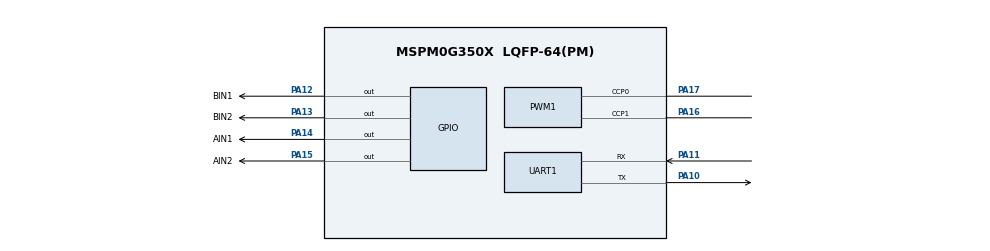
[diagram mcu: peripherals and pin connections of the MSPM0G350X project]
/**
 * @cliArgs --device "MSPM0G350X" --part "Default" --package "LQFP-64(PM)" --product "mspm0_sdk@2.05.01.01"
 * @versions {"tool":"1.24.0+4110"}
 */

/**
 * Import the modules used in this configuration.
 */
const GPIO   = scripting.addModule("/ti/driverlib/GPIO", {}, false);
const GPIO1  = GPIO.addInstance();
const GPIO2  = GPIO.addInstance();
const GPIO3  = GPIO.addInstance();
const GPIO4  = GPIO.addInstance();
const GPIO5  = GPIO.addInstance();
const GPIO6  = GPIO.addInstance();
const GPIO7  = GPIO.addInstance();
const GPIO8  = GPIO.addInstance();
const GPIO9  = GPIO.addInstance();
const PWM    = scripting.addModule("/ti/driverlib/PWM", {}, false);
const PWM1   = PWM.addInstance();
const SYSCTL = scripting.addModule("/ti/driverlib/SYSCTL");
const TIMER  = scripting.addModule("/ti/driverlib/TIMER", {}, false);
const TIMER1 = TIMER.addInstance();
const UART   = scripting.addModule("/ti/driverlib/UART", {}, false);
const UART1  = UART.addInstance();

/**
 * Write custom configuration values to the imported modules.
 */
const divider9       = system.clockTree["UDIV"];
divider9.divideValue = 2;

const mux4       = system.clockTree["EXHFMUX"];
mux4.inputSelect = "EXHFMUX_XTAL";

const mux8       = system.clockTree["HSCLKMUX"];
mux8.inputSelect = "HSCLKMUX_SYSPLL2X";

const mux12       = system.clockTree["SYSPLLMUX"];
mux12.inputSelect = "zSYSPLLMUX_HFCLK";

const pinFunction4        = system.clockTree["HFXT"];
pinFunction4.inputFreq    = 40;
pinFunction4.enable       = true;
pinFunction4.HFCLKMonitor = true;
pinFunction4.HFXTStartup  = 20;

GPIO1.$name                          = "LED1";
GPIO1.associatedPins[0].ioStructure  = "SD";
GPIO1.associatedPins[0].assignedPort = "PORTB";
GPIO1.associatedPins[0].assignedPin  = "22";
GPIO1.associatedPins[0].$name        = "PIN_22";

const Board = scripting.addModule("/ti/driverlib/Board", {}, false);

GPIO2.$name                          = "TB6612";
GPIO2.port                           = "PORTA";
GPIO2.associatedPins.create(4);
GPIO2.associatedPins[0].$name        = "AIN1";
GPIO2.associatedPins[0].initialValue = "SET";
GPIO2.associatedPins[0].assignedPin  = "14";
GPIO2.associatedPins[0].pin.$assign  = "PA14";
GPIO2.associatedPins[1].$name        = "AIN2";
GPIO2.associatedPins[1].initialValue = "SET";
GPIO2.associatedPins[1].assignedPin  = "15";
GPIO2.associatedPins[1].pin.$assign  = "PA15";
GPIO2.associatedPins[2].$name        = "BIN1";
GPIO2.associatedPins[2].initialValue = "SET";
GPIO2.associatedPins[2].assignedPin  = "12";
GPIO2.associatedPins[2].pin.$assign  = "PA12";
GPIO2.associatedPins[3].$name        = "BIN2";
GPIO2.associatedPins[3].initialValue = "SET";
GPIO2.associatedPins[3].assignedPin  = "13";
GPIO2.associatedPins[3].pin.$assign  = "PA13";

GPIO3.$name                          = "ENCODER1A";
GPIO3.associatedPins[0].direction    = "INPUT";
GPIO3.associatedPins[0].assignedPort = "PORTA";
GPIO3.associatedPins[0].assignedPin  = "21";
GPIO3.associatedPins[0].interruptEn  = true;
GPIO3.associatedPins[0].polarity     = "FALL";
GPIO3.associatedPins[0].$name        = "A1";

GPIO4.$name                          = "ENCODER1B";
GPIO4.associatedPins[0].direction    = "INPUT";
GPIO4.associatedPins[0].assignedPort = "PORTB";
GPIO4.associatedPins[0].polarity     = "FALL";
GPIO4.associatedPins[0].assignedPin  = "18";
GPIO4.associatedPins[0].$name        = "B1";

GPIO5.$name                          = "ENCODER2A";
GPIO5.associatedPins[0].direction    = "INPUT";
GPIO5.associatedPins[0].$name        = "A2";
GPIO5.associatedPins[0].assignedPort = "PORTB";
GPIO5.associatedPins[0].assignedPin  = "23";
GPIO5.associatedPins[0].interruptEn  = true;
GPIO5.associatedPins[0].polarity     = "FALL";

GPIO6.$name                          = "ENCODER2B";
GPIO6.associatedPins[0].$name        = "B2";
GPIO6.associatedPins[0].direction    = "INPUT";
GPIO6.associatedPins[0].assignedPort = "PORTB";
GPIO6.associatedPins[0].assignedPin  = "26";

GPIO7.port                          = "PORTA";
GPIO7.$name                         = "SENSOR";
GPIO7.associatedPins.create(5);
GPIO7.associatedPins[0].direction   = "INPUT";
GPIO7.associatedPins[0].assignedPin = "24";
GPIO7.associatedPins[0].$name       = "A";
GPIO7.associatedPins[1].direction   = "INPUT";
GPIO7.associatedPins[1].assignedPin = "25";
GPIO7.associatedPins[1].$name       = "B";
GPIO7.associatedPins[2].direction   = "INPUT";
GPIO7.associatedPins[2].assignedPin = "26";
GPIO7.associatedPins[2].$name       = "C";
GPIO7.associatedPins[3].direction   = "INPUT";
GPIO7.associatedPins[3].assignedPin = "27";
GPIO7.associatedPins[3].$name       = "D";
GPIO7.associatedPins[4].$name       = "E";
GPIO7.associatedPins[4].direction   = "INPUT";
GPIO7.associatedPins[4].assignedPin = "22";

GPIO8.$name                         = "SENSOR2";
GPIO8.port                          = "PORTB";
GPIO8.associatedPins.create(2);
GPIO8.associatedPins[0].$name       = "L";
GPIO8.associatedPins[0].direction   = "INPUT";
GPIO8.associatedPins[0].assignedPin = "24";
GPIO8.associatedPins[1].$name       = "R";
GPIO8.associatedPins[1].direction   = "INPUT";
GPIO8.associatedPins[1].assignedPin = "25";

GPIO9.$name                              = "KEY";
GPIO9.associatedPins.create(6);
GPIO9.associatedPins[0].$name            = "KEY1";
GPIO9.associatedPins[0].direction        = "INPUT";
GPIO9.associatedPins[0].internalResistor = "PULL_UP";
GPIO9.associatedPins[0].assignedPort     = "PORTA";
GPIO9.associatedPins[0].interruptEn      = true;
GPIO9.associatedPins[0].assignedPin      = "28";
GPIO9.associatedPins[0].polarity         = "RISE";
GPIO9.associatedPins[1].$name            = "KEY2";
GPIO9.associatedPins[1].direction        = "INPUT";
GPIO9.associatedPins[1].internalResistor = "PULL_UP";
GPIO9.associatedPins[1].assignedPort     = "PORTA";
GPIO9.associatedPins[1].interruptEn      = true;
GPIO9.associatedPins[1].polarity         = "RISE";
GPIO9.associatedPins[1].assignedPin      = "31";
GPIO9.associatedPins[2].$name            = "KEY3";
GPIO9.associatedPins[2].direction        = "INPUT";
GPIO9.associatedPins[2].internalResistor = "PULL_UP";
GPIO9.associatedPins[2].interruptEn      = true;
GPIO9.associatedPins[2].polarity         = "RISE";
GPIO9.associatedPins[2].assignedPort     = "PORTA";
GPIO9.associatedPins[2].assignedPin      = "8";
GPIO9.associatedPins[3].internalResistor = "PULL_UP";
GPIO9.associatedPins[3].direction        = "INPUT";
GPIO9.associatedPins[3].interruptEn      = true;
GPIO9.associatedPins[3].polarity         = "RISE";
GPIO9.associatedPins[3].assignedPort     = "PORTA";
GPIO9.associatedPins[3].assignedPin      = "9";
GPIO9.associatedPins[3].$name            = "KEY4";
GPIO9.associatedPins[4].$name            = "KEY5";
GPIO9.associatedPins[4].direction        = "INPUT";
GPIO9.associatedPins[4].interruptEn      = true;
GPIO9.associatedPins[4].polarity         = "RISE";
GPIO9.associatedPins[4].internalResistor = "PULL_UP";
GPIO9.associatedPins[4].assignedPort     = "PORTB";
GPIO9.associatedPins[4].assignedPin      = "6";
GPIO9.associatedPins[5].$name            = "KEY6";
GPIO9.associatedPins[5].direction        = "INPUT";
GPIO9.associatedPins[5].assignedPort     = "PORTB";
GPIO9.associatedPins[5].assignedPin      = "7";
GPIO9.associatedPins[5].interruptEn      = true;
GPIO9.associatedPins[5].polarity         = "RISE";
GPIO9.associatedPins[5].internalResistor = "PULL_UP";

PWM1.$name                      = "PWM_0";
PWM1.timerStartTimer            = true;
PWM1.clockDivider               = 8;
PWM1.peripheral.$assign         = "TIMA1";
PWM1.peripheral.ccp0Pin.$assign = "PA17";
PWM1.peripheral.ccp1Pin.$assign = "PA16";
PWM1.PWM_CHANNEL_0.$name        = "ti_driverlib_pwm_PWMTimerCC0";
PWM1.PWM_CHANNEL_0.invert       = true;
PWM1.PWM_CHANNEL_1.$name        = "ti_driverlib_pwm_PWMTimerCC1";
PWM1.PWM_CHANNEL_1.invert       = true;
PWM1.ccp0PinConfig.$name        = "ti_driverlib_gpio_GPIOPinGeneric2";
PWM1.ccp1PinConfig.$name        = "ti_driverlib_gpio_GPIOPinGeneric3";

SYSCTL.forceDefaultClkConfig = true;
SYSCTL.clockTreeEn           = true;
SYSCTL.validateClkStatus     = true;
scripting.suppress("For best practices when the CPUCLK is running at 32MHz and above, clear the flash status bit using DL_FlashCTL_executeClearStatus\\(\\) before executing any flash operation\\. Otherwise there may be false positives\\.", SYSCTL);

TIMER1.$name              = "TIMER_0";
TIMER1.timerClkPrescale   = 250;
TIMER1.timerStartTimer    = true;
TIMER1.interrupts         = ["ZERO"];
TIMER1.timerClkDiv        = 4;
TIMER1.timerMode          = "PERIODIC";
TIMER1.timerPeriod        = "500 ms";
TIMER1.peripheral.$assign = "TIMG0";

UART1.$name                        = "UART_0";
UART1.targetBaudRate               = 115200;
UART1.peripheral.$assign           = "UART0";
UART1.peripheral.rxPin.$assign     = "PA11";
UART1.peripheral.txPin.$assign     = "PA10";
UART1.txPinConfig.$name            = "ti_driverlib_gpio_GPIOPinGeneric0";
UART1.txPinConfig.enableConfig     = true;
UART1.txPinConfig.internalResistor = "PULL_UP";
UART1.rxPinConfig.$name            = "ti_driverlib_gpio_GPIOPinGeneric1";
UART1.rxPinConfig.enableConfig     = true;
UART1.rxPinConfig.internalResistor = "PULL_UP";

/**
 * Pinmux solution for unlocked pins/peripherals. This ensures that minor changes to the automatic solver in a future
 * version of the tool will not impact the pinmux you originally saw.  These lines can be completely deleted in order to
 * re-solve from scratch.
 */
pinFunction4.peripheral.$suggestSolution           = "SYSCTL";
pinFunction4.peripheral.hfxInPin.$suggestSolution  = "PA5";
pinFunction4.peripheral.hfxOutPin.$suggestSolution = "PA6";
GPIO1.associatedPins[0].pin.$suggestSolution       = "PB22";
Board.peripheral.$suggestSolution                  = "DEBUGSS";
Board.peripheral.swclkPin.$suggestSolution         = "PA20";
Board.peripheral.swdioPin.$suggestSolution         = "PA19";
GPIO3.associatedPins[0].pin.$suggestSolution       = "PA21";
GPIO4.associatedPins[0].pin.$suggestSolution       = "PB18";
GPIO5.associatedPins[0].pin.$suggestSolution       = "PB23";
GPIO6.associatedPins[0].pin.$suggestSolution       = "PB26";
GPIO7.associatedPins[0].pin.$suggestSolution       = "PA24";
GPIO7.associatedPins[1].pin.$suggestSolution       = "PA25";
GPIO7.associatedPins[2].pin.$suggestSolution       = "PA26";
GPIO7.associatedPins[3].pin.$suggestSolution       = "PA27";
GPIO7.associatedPins[4].pin.$suggestSolution       = "PA22";
GPIO8.associatedPins[0].pin.$suggestSolution       = "PB24";
GPIO8.associatedPins[1].pin.$suggestSolution       = "PB25";
GPIO9.associatedPins[0].pin.$suggestSolution       = "PA28";
GPIO9.associatedPins[1].pin.$suggestSolution       = "PA31";
GPIO9.associatedPins[2].pin.$suggestSolution       = "PA8";
GPIO9.associatedPins[3].pin.$suggestSolution       = "PA9";
GPIO9.associatedPins[4].pin.$suggestSolution       = "PB6";
GPIO9.associatedPins[5].pin.$suggestSolution       = "PB7";
